# earlgrey register map
Vendor: lowRISC; File version: 0.1
CPU: ibex rev01, little endian, no MPU, no FPU, VTOR, 2 interrupt priority bits, 2 interrupts
Registers are 32-bit, read-write, no defined reset value unless marked. A register's access mark holds for its fields unless they carry their own. Offsets are from the block's base; [hi:lo] are bit positions; {n}, {i} and the like mark numbered series; 'fields as' and 'values as' point back to an identical list.

## FLASH_CTRL — Interfaces and manages integrated non-volatile flash memory; supports scrambling, integrity, and secure wipe
Base 0x41000000
0x40 DIS — Disable flash functionality
  [3:0] VAL — Disables flash functionality completely.This is a shortcut mechanism used by the software to completelykill flash in case of emergency.Since this register is rw0c instead of rw, to disable, write any value in the form of0xxx or xxx0, where x could be either 0 or 1.
0x44 EXEC — Controls whether flash can be used for code execution fetches
  [31:0] EN — A value of 0xa26a38f7 allows flash to be used for code execution.Any other value prevents code execution.
0x48 INIT — Controller init register
  [0] VAL — Initializes the flash controller.During the initialization process, the flash controller requests the address and datascramble keys and reads out the root seeds stored in flash before allowing other usageof the flash controller.When the initialization sequence is complete, the flash read buffers are enabledand turned on.
0x4C CTRL_REGWEN ro — Controls the configurability of the !!CONTROL register.This register ensures the contents of !!CONTROL cannot be changed by software once a flashoperation has begun.It unlocks whenever the existing flash operation completes, regardless of success or error.
  [0] EN — Configuration enable.This bit defaults to 1 and is set to 0 by hardware when flash operation is initiated.When the controller completes the flash operation, this bit is setback to 1 to allow software configuration of !!CONTROL
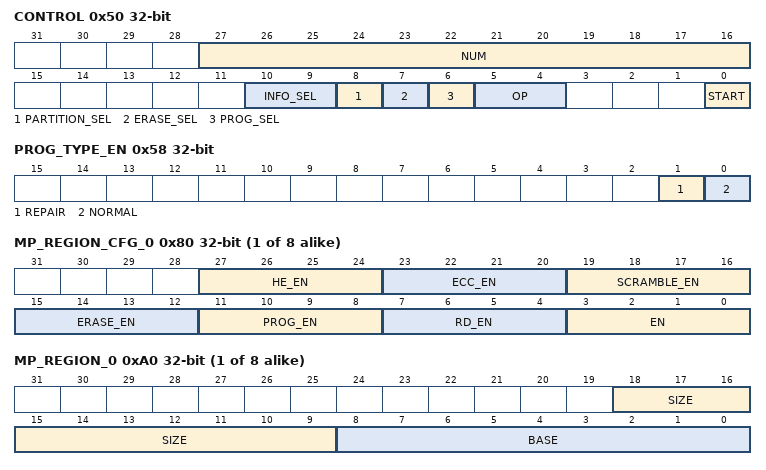
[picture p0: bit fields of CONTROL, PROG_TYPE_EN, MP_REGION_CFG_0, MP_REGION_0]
0x50 CONTROL
  [27:16] NUM — One fewer than the number of bus words the flash operation should read or program.For example, to read 10 words, software should program this field with the value 9.
  [10:9] INFO_SEL — Informational partions can have multiple types.This field selects the info type to be accessed.
  [8] PARTITION_SEL — When doing a read, program or page erase operation, selects either info or data partition for operation.When 0, select data partition - this is the portion of flash that is accessible both by the host and by the controller.When 1, select info partition - this is the portion of flash that is only accessible by the controller.When doing a bank erase operation, selects info partition also for erase.When 0, bank erase only erases data partition.When 1, bank erase erases data partition and info partition.
  [7] ERASE_SEL — Flash erase operation type selection
  [6] PROG_SEL — Flash program operation type selection
  [5:4] OP — Flash operation selection
  [0] START — Start flash transaction. This bit shall only be set at the same time or after the otherfields of the !!CONTROL register and !!ADDR have been programmed.
0x54 ADDR — Address for flash operation
  [19:0] START — Start address of a flash transaction. This is a byte address relative to the flashonly. Ie, an address of 0 will access address 0 of the requested partition.For read operations, the flash controller will truncate to the closest, lower wordaligned address. For example, if 0x13 is supplied, the controller will perform aread at address 0x10.Program operations behave similarly, the controller does not have read modified writesupport.For page erases, the controller will truncate to the closest lower page alignedaddress. Similarly for bank erases, the controller will truncate to the closestlower bank aligned address.
0x58 PROG_TYPE_EN — Enable different program types
  [1] REPAIR — Repair prog type available
  [0] NORMAL — Normal prog type available
0x5C ERASE_SUSPEND — Suspend erase
  [0] REQ — When 1, request erase suspend.If no erase ongoing, the request is immediately cleared by hardwareIf erase ongoing, the request is fed to the flash_phy and cleared when the suspend is handled.
{0x60+4i} REGION_CFG_REGWEN_{i} (i=0..7) — Memory region registers configuration enable.
  [0] REGION — Region register write enable. Once set to 0, it can longer be configured to 1
{0x80+4i} MP_REGION_CFG_{i} (i=0..7) — Memory property configuration for data partition
  [27:24] HE_EN — Region is high endurance enabled.
  [23:20] ECC_EN — Region is integrity checked and reliability ECC enabled.
  [19:16] SCRAMBLE_EN — Region is scramble enabled.
  [15:12] ERASE_EN — Region can be erased
  [11:8] PROG_EN — Region can be programmed
  [7:4] RD_EN — Region can be read
  [3:0] EN — Region enabled, following fields apply.If region is disabled, it is not matched against any incoming transaction.
{0xA0+4i} MP_REGION_{i} (i=0..7) — Memory base and size configuration for data partition
  [18:9] SIZE — Region size in number of pages.For example, if base is 0 and size is 1, then the region is defined by page 0.If base is 0 and size is 2, then the region is defined by pages 0 and 1.
  [8:0] BASE — Region base page. Note the granularity is page, not byte or word
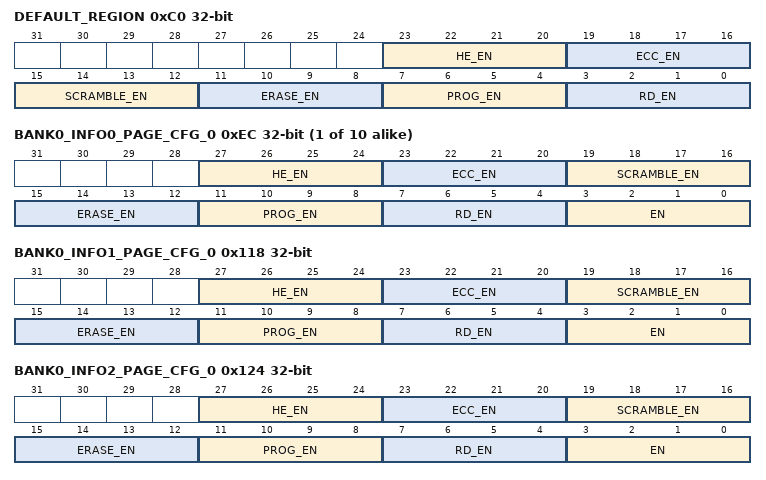
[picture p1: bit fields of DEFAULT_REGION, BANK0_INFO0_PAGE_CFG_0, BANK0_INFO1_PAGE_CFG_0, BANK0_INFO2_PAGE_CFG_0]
0xC0 DEFAULT_REGION — Default region properties
  [23:20] HE_EN — Region is high endurance enabled.
  [19:16] ECC_EN — Region is ECC enabled (both integrity and reliability ECC).
  [15:12] SCRAMBLE_EN — Region is scramble enabled.
  [11:8] ERASE_EN — Region can be erased
  [7:4] PROG_EN — Region can be programmed
  [3:0] RD_EN — Region can be read
{0xC4+4i} BANK0_INFO0_REGWEN_{i} (i=0..9) — Memory region registers configuration enable.
  [0] REGION — Info0 page write enable. Once set to 0, it can longer be configured to 1
{0xEC+4i} BANK0_INFO0_PAGE_CFG_{i} (i=0..9) — Memory property configuration for info partition in bank0, Unlike data partition, each page is individually configured.
  [27:24] HE_EN — Region is high endurance enabled.
  [23:20] ECC_EN — Region is ECC enabled (both integrity and reliability ECC).
  [19:16] SCRAMBLE_EN — Region is scramble enabled.
  [15:12] ERASE_EN — Region can be erased
  [11:8] PROG_EN — Region can be programmed
  [7:4] RD_EN — Region can be read
  [3:0] EN — Region enabled, following fields apply
0x114 BANK0_INFO1_REGWEN_0 — Memory region registers configuration enable.
  [0] REGION — Info1 page write enable. Once set to 0, it can longer be configured to 1
0x118 BANK0_INFO1_PAGE_CFG_0 — Memory property configuration for info partition in bank0, Unlike data partition, each page is individually configured.
  fields as BANK0_INFO0_PAGE_CFG_0
0x11C BANK0_INFO2_REGWEN_0 — Memory region registers configuration enable.
  [0] REGION — Info2 page write enable. Once set to 0, it can longer be configured to 1
0x120 BANK0_INFO2_REGWEN_1 — Memory region registers configuration enable.
  fields as BANK0_INFO2_REGWEN_0
0x124 BANK0_INFO2_PAGE_CFG_0 — Memory property configuration for info partition in bank0, Unlike data partition, each page is individually configured.
  fields as BANK0_INFO0_PAGE_CFG_0
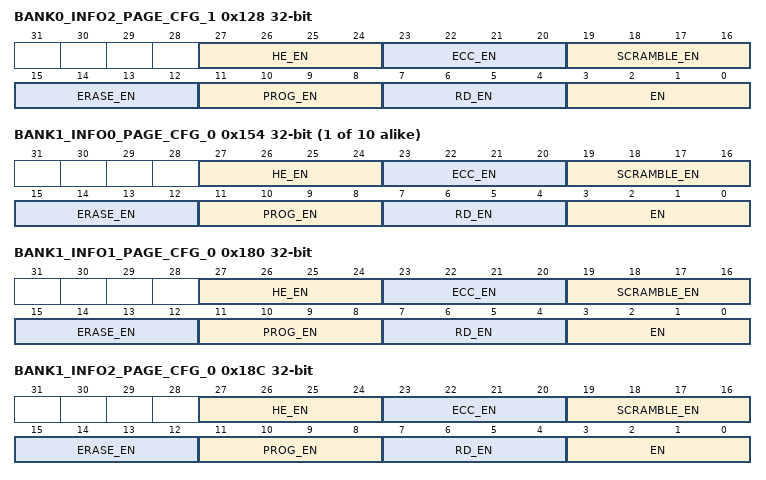
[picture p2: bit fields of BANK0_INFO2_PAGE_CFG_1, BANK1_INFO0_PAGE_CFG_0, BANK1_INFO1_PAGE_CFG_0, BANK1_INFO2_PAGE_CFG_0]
0x128 BANK0_INFO2_PAGE_CFG_1 — Memory property configuration for info partition in bank0, Unlike data partition, each page is individually configured.
  fields as BANK0_INFO0_PAGE_CFG_0
{0x12C+4i} BANK1_INFO0_REGWEN_{i} (i=0..9) — Memory region registers configuration enable.
  fields as BANK0_INFO0_REGWEN_0
{0x154+4i} BANK1_INFO0_PAGE_CFG_{i} (i=0..9) — Memory property configuration for info partition in bank1, Unlike data partition, each page is individually configured.
  fields as BANK0_INFO0_PAGE_CFG_0
0x17C BANK1_INFO1_REGWEN_0 — Memory region registers configuration enable.
  fields as BANK0_INFO1_REGWEN_0
0x180 BANK1_INFO1_PAGE_CFG_0 — Memory property configuration for info partition in bank1, Unlike data partition, each page is individually configured.
  fields as BANK0_INFO0_PAGE_CFG_0
0x184 BANK1_INFO2_REGWEN_0 — Memory region registers configuration enable.
  fields as BANK0_INFO2_REGWEN_0
0x188 BANK1_INFO2_REGWEN_1 — Memory region registers configuration enable.
  fields as BANK0_INFO2_REGWEN_0
0x18C BANK1_INFO2_PAGE_CFG_0 — Memory property configuration for info partition in bank1, Unlike data partition, each page is individually configured.
  fields as BANK0_INFO0_PAGE_CFG_0
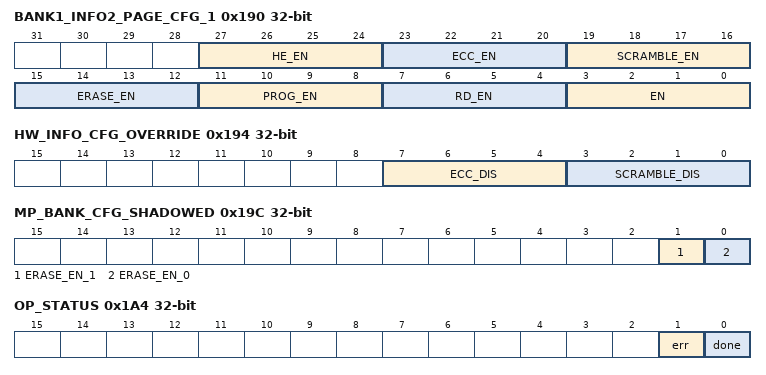
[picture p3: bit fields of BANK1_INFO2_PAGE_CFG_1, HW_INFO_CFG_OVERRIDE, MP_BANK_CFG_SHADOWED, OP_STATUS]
0x190 BANK1_INFO2_PAGE_CFG_1 — Memory property configuration for info partition in bank1, Unlike data partition, each page is individually configured.
  fields as BANK0_INFO0_PAGE_CFG_0
0x194 HW_INFO_CFG_OVERRIDE — HW interface info configuration rule overrides
  [7:4] ECC_DIS — The hardwired hardware info configuration rules for ECC enable are logically AND'd withthis field.If the hardware rules hardwires ECC to enable, we can disable via software if needed.By default this field is false.
  [3:0] SCRAMBLE_DIS — The hardwired hardware info configuration rules for scramble enable are logically AND'd withthis field.If the hardware rules hardwires scramble to enable, we can disable via software if needed.By default this field is false.
0x198 BANK_CFG_REGWEN — Bank configuration registers configuration enable.
  [0] BANK — Bank register write enable. Once set to 0, it can longer be configured to 1
0x19C MP_BANK_CFG_SHADOWED — Memory properties bank configuration
  [1] ERASE_EN_1 — Bank wide erase enable
  [0] ERASE_EN_0 — Bank wide erase enable
0x1A4 OP_STATUS — Flash Operation Status
  [1] err — Flash operation error. Set by HW, cleared by SW. See !!ERR_CODE for more details.
  [0] done — Flash operation done. Set by HW, cleared by SW
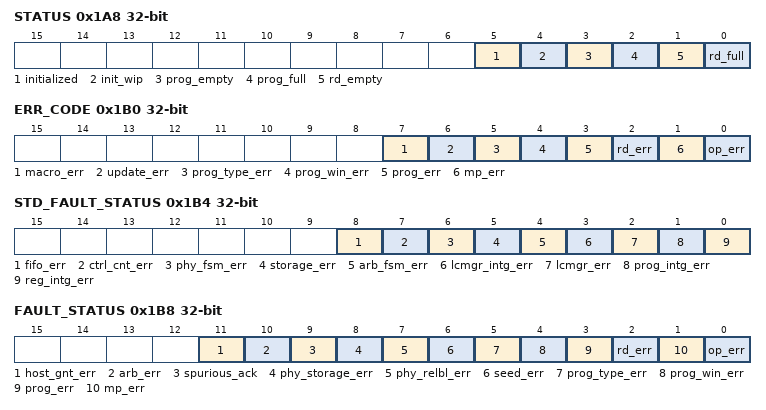
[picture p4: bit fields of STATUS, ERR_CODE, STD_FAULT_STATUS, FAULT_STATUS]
0x1A8 STATUS ro — Flash Controller Status
  [5] initialized — Flash controller initialized
  [4] init_wip — Flash controller undergoing init, inclusive of phy init
  [3] prog_empty — Flash program FIFO empty, software must provide data
  [2] prog_full — Flash program FIFO full
  [1] rd_empty — Flash read FIFO empty
  [0] rd_full — Flash read FIFO full, software must consume data
0x1AC DEBUG_STATE ro — Current flash fsm state
  [10:0] lcmgr_state — Current lcmgr interface staet
0x1B0 ERR_CODE — Flash error code register.This register tabulates detailed error status of the flash.This is separate from !!OP_STATUS, which is used to indicate the current state of the software initiatedflash operation.Note, all errors in this register are considered recoverable errors, ie, errors that could have beengenerated by software.
  [7] macro_err — A recoverable error has been encountered in the flash macro.Please read the flash macro status registers for more details.
  [6] update_err — A shadow register encountered an update error.This is an asynchronous error.
  [5] prog_type_err — Flash program selected unavailable type, see !!PROG_TYPE_EN.This is a synchronous error.
  [4] prog_win_err — Flash program has a window resolution error. Ie, the start of programand end of program are in different windows. Please check !!ERR_ADDR.This is a synchronous error.
  [3] prog_err — Flash program has an error.This could be a program integrity error, see !!STD_FAULT_STATUS.This is a synchronous error.
  [2] rd_err — Flash read has an error.This could be a reliability ECC error or an storage integrity errorencountered during a software issued controller read, see !!STD_FAULT_STATUS.See !!ERR_ADDR for exact address.This is a synchronous error.
  [1] mp_err — Flash access has encountered an access permission error.Please see !!ERR_ADDR for exact address.This is a synchronous error.
  [0] op_err — Software has supplied an undefined operation.See !!CONTROL.OP for list of valid operations.
0x1B4 STD_FAULT_STATUS ro — This register tabulates standard fault status of the flash.These represent errors that occur in the standard structures of the design.For example fsm integrity, counter integrity and tlul integrity.
  [8] fifo_err — Flash primitive fifo's have encountered a count error.
  [7] ctrl_cnt_err — Flash ctrl read/prog has encountered a count error.
  [6] phy_fsm_err — A flash phy fsm has encountered a sparse encoding error.
  [5] storage_err — A shadow register encountered a storage error.
  [4] arb_fsm_err — The arbiter fsm has encountered a sparse encoding error.
  [3] lcmgr_intg_err — The life cycle management interface has encountered a transmissionintegrity error. This is an integrity error on the generated integrityduring a life cycle management interface read.
  [2] lcmgr_err — The life cycle management interface has encountered a fatal error.The error is either an FSM sparse encoding error or a count error.
  [1] prog_intg_err — The flash controller encountered a program data transmission integrity error.
  [0] reg_intg_err — The flash controller encountered a register integrity error.
0x1B8 FAULT_STATUS ro — This register tabulates customized fault status of the flash.These are errors that are impossible to have been caused by software or unrecoverablein nature.
  [11] host_gnt_err — A host transaction was granted with illegal properties.
  [10] arb_err — The phy arbiter encountered inconsistent results.
  [9] spurious_ack — The flash emitted an unexpected acknowledgement.
  [8] phy_storage_err — The flash macro encountered a storage integrity ECC error.
  [7] phy_relbl_err — The flash macro encountered a storage reliability ECC error.
  [6] seed_err — The seed reading process encountered an unexpected error.
  [5] prog_type_err — The flash life cycle management interface encountered a program type error.A program type not supported by the flash macro was issued.
  [4] prog_win_err — The flash life cycle management interface encountered a program resolution error.
  [3] prog_err — The flash life cycle management interface encountered a program error.This could be a program integirty eror, see !!STD_FAULT_STATUS for more details.
  [2] rd_err — The flash life cycle management interface encountered a read error.This could be a reliability ECC error or an integrity ECC errorencountered during a read, see !!STD_FAULT_STATUS for more details.
  [1] mp_err — The flash life cycle management interface encountered a memory permission error.
  [0] op_err — The flash life cycle management interface has supplied an undefined operation.See !!CONTROL.OP for list of valid operations.
0x1BC ERR_ADDR ro — Synchronous error address
  [19:0] Value
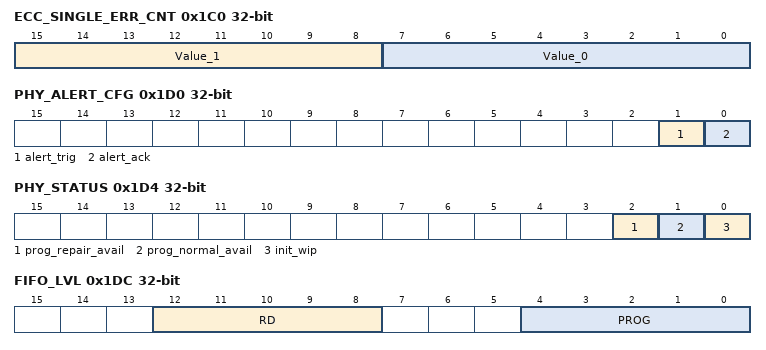
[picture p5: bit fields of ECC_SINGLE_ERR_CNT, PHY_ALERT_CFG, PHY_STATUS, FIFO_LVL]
0x1C0 ECC_SINGLE_ERR_CNT — Total number of single bit ECC error count
  [15:8] Value_1 — This count will not wrap when saturated
  [7:0] Value_0 — This count will not wrap when saturated
0x1C8 ECC_SINGLE_ERR_ADDR_0 ro — Latest address of ECC single err
  [19:0] Value — Latest single error address for this bank
0x1CC ECC_SINGLE_ERR_ADDR_1 ro — Latest address of ECC single err
  [19:0] Value — Latest single error address for this bank
0x1D0 PHY_ALERT_CFG — Phy alert configuration
  [1] alert_trig — Trigger flash phy alert
  [0] alert_ack — Acknowledge flash phy alert
0x1D4 PHY_STATUS ro — Flash Phy Status
  [2] prog_repair_avail — Program repair supported
  [1] prog_normal_avail — Normal program supported
  [0] init_wip — Flash phy controller initializing
0x1D8 Scratch — Flash Controller Scratch
  [31:0] data — Flash ctrl scratch register
0x1DC FIFO_LVL — Programmable depth where FIFOs should generate interrupts
  [12:8] RD — When the read FIFO fills to this level, trigger an interrupt.Default value is set such that interrupt does not trigger at reset.
  [4:0] PROG — When the program FIFO drains to this level, trigger an interrupt.Default value is set such that interrupt does not trigger at reset.
0x1E0 FIFO_RST — Reset for flash controller FIFOs
  [0] EN — Active high resets for both program and read FIFOs. This is especially useful after the controllerencounters an error of some kind.This bit will hold the FIFO in reset as long as it is set.
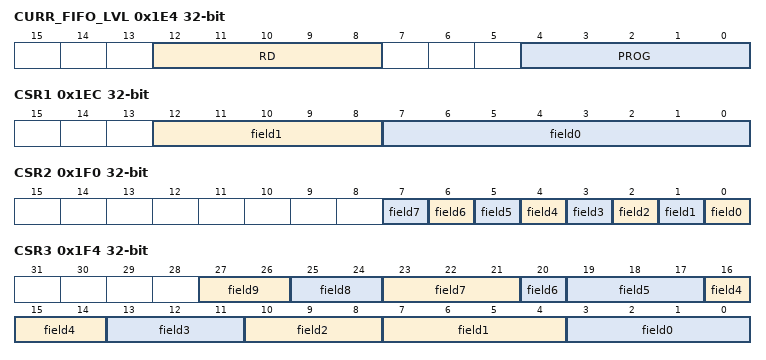
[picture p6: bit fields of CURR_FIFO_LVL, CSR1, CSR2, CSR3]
0x1E4 CURR_FIFO_LVL ro — Current program and read fifo depth
  [12:8] RD — Current read fifo depth
  [4:0] PROG — Current program fifo depth
0x1E8 CSR0_REGWEN
  [0] field0
0x1EC CSR1
  [12:8] field1, [7:0] field0
0x1F0 CSR2
  [n] field{n} (n=0..7)
0x1F4 CSR3
  [27:26] field9, [25:24] field8, [23:21] field7, [20] field6, [3n+4:3n+2] field{n} (n=2..5), [7:4] field1, [3:0] field0
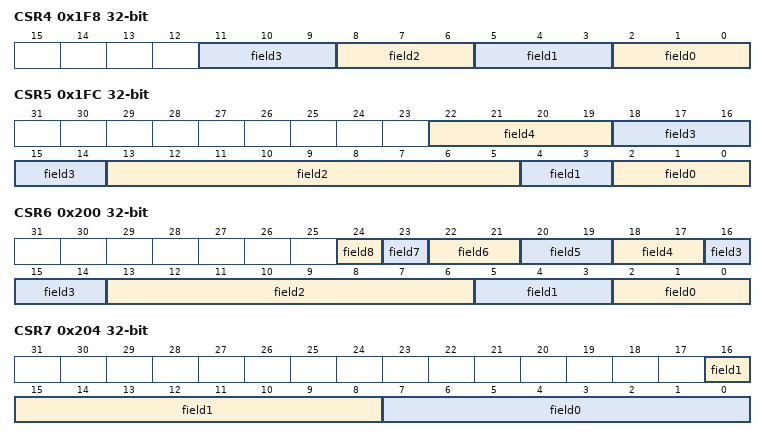
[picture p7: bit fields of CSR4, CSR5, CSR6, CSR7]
0x1F8 CSR4
  [3n+2:3n] field{n} (n=0..3)
0x1FC CSR5
  [22:19] field4, [18:14] field3, [13:5] field2, [4:3] field1, [2:0] field0
0x200 CSR6
  [24] field8, [23] field7, [22:21] field6, [20:19] field5, [18:17] field4, [16:14] field3, [13:6] field2, [5:3] field1, [2:0] field0
0x204 CSR7
  [16:8] field1, [7:0] field0
{0x1E8+4i} CSR{i} (i=8..11)
  [31:0] field0
0x218 CSR12
  [9:0] field0
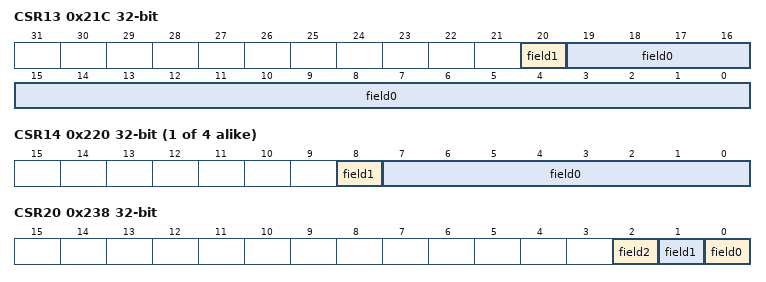
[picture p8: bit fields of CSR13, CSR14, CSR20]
0x21C CSR13
  [20] field1, [19:0] field0
{0x1E8+4i} CSR{i} (i=14..17)
  [8] field1, [7:0] field0
0x230 CSR18
  [0] field0
0x234 CSR19
  [0] field0
0x238 CSR20
  [2] field2, [1] field1, [0] field0
